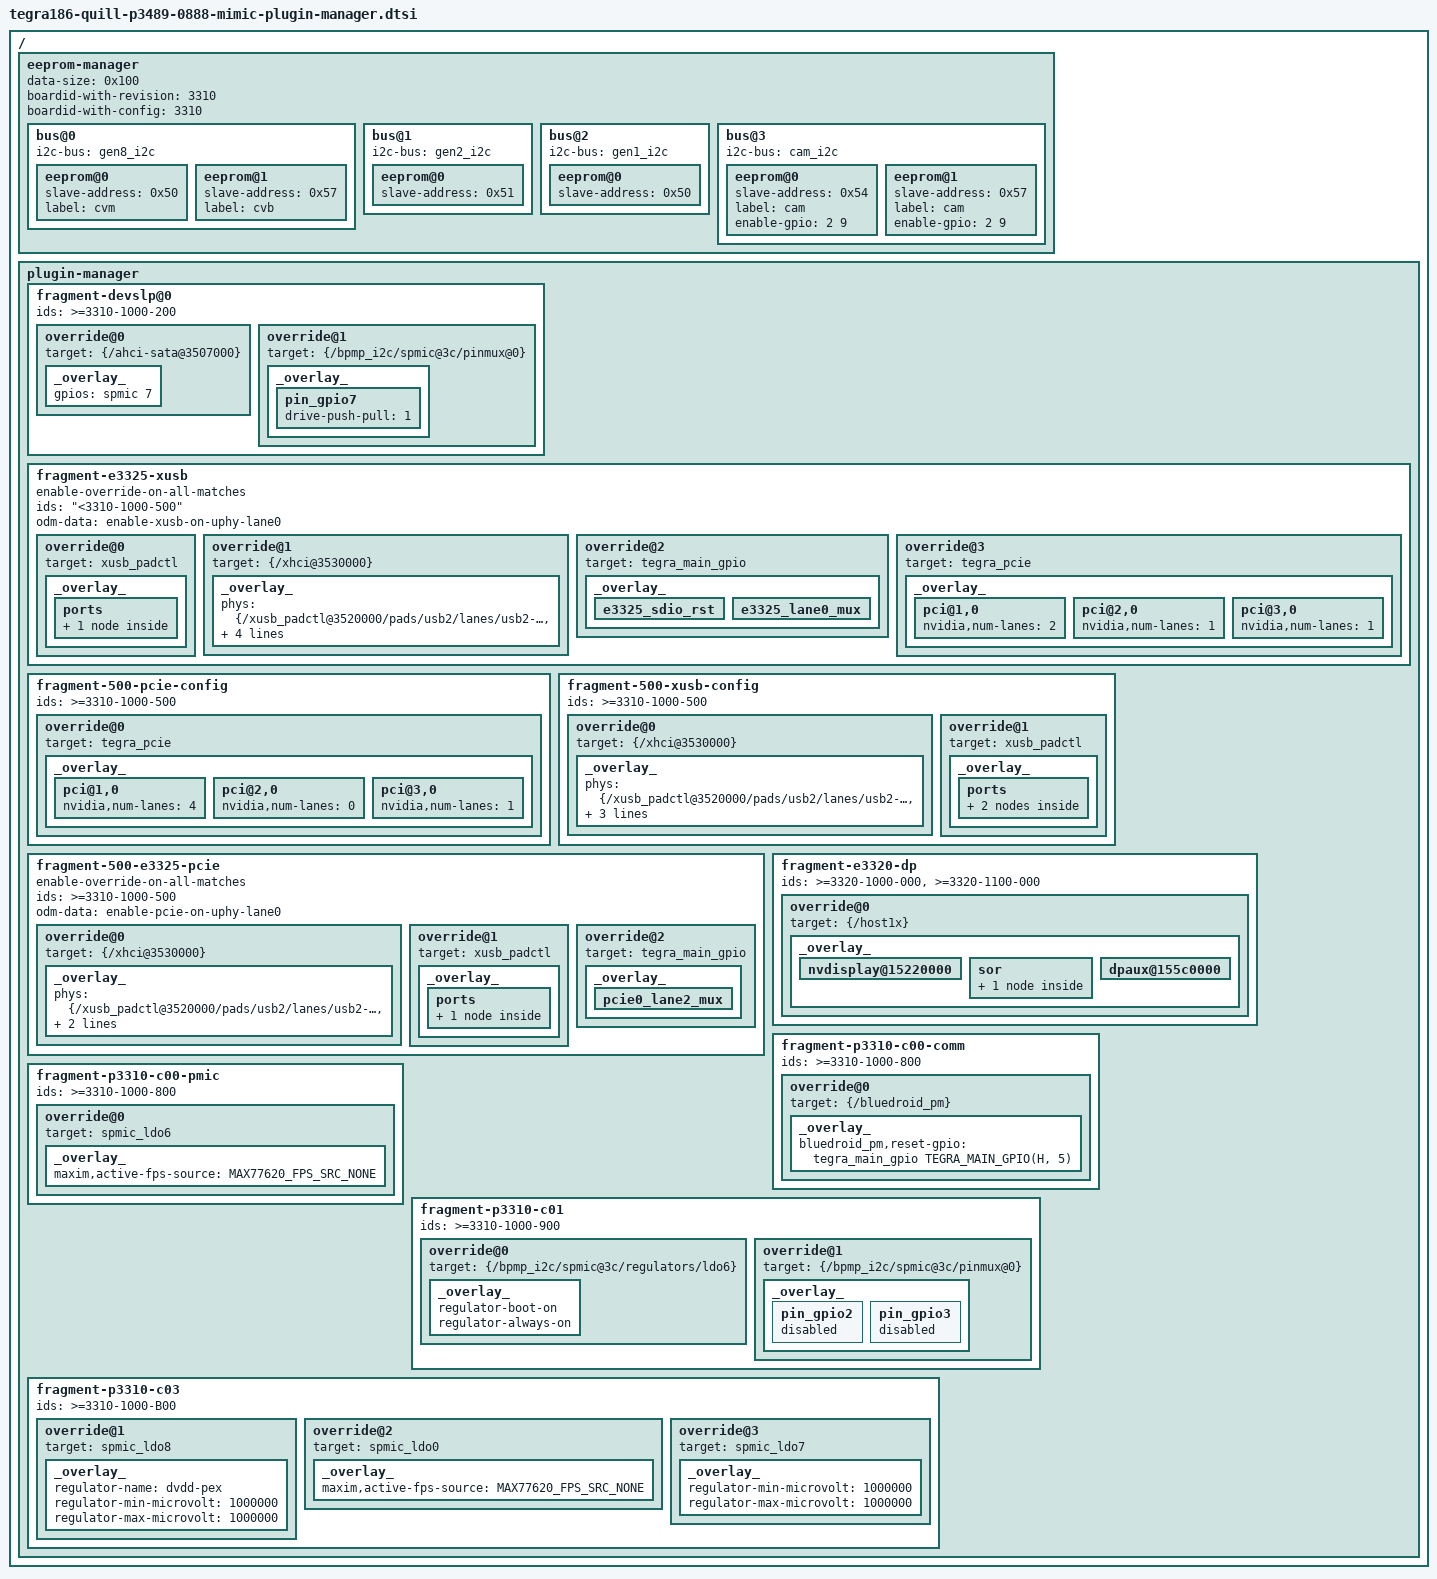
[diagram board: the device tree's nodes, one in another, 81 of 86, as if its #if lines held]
/*
 * tegra186-quill-p3489-0888-mimic-plugin-manager.dtsi: Lightning mimic plugin manager
 *
 * Copyright (c) 2015-2019, NVIDIA CORPORATION.  All rights reserved.
 *
 * This program is free software; you can redistribute it and/or modify
 * it under the terms of the GNU General Public License as published by
 * the Free Software Foundation; version 2 of the License.
 *
 * This program is distributed in the hope that it will be useful, but WITHOUT
 * ANY WARRANTY; without even the implied warranty of MERCHANTABILITY or
 * FITNESS FOR A PARTICULAR PURPOSE.  See the GNU General Public License for
 * more details.
 */

#include "tegra186-soc-prod-plugin-manager.dtsi"
#include "tegra186-odm-data-plugin-manager.dtsi"
#include "tegra186-quill-p3310-1000-300-plugin-manager.dtsi"

/ {
	eeprom-manager {
		data-size = <0x100>;
		boardid-with-revision = <3310>;
		boardid-with-config = <3310>;
		bus@0 {
			i2c-bus = <&gen8_i2c>;
			eeprom@0 {
				slave-address = <0x50>;
				label = "cvm";
			};
			eeprom@1 {
				slave-address = <0x57>;
				label = "cvb";
			};
		};
		bus@1 {
			i2c-bus = <&gen2_i2c>;
			eeprom@0 {
				slave-address = <0x51>;
			};
		};
		bus@2 {
			i2c-bus = <&gen1_i2c>;
			eeprom@0 {
				slave-address = <0x50>;
			};
		};
		bus@3 {
			i2c-bus = <&cam_i2c>;
			eeprom@0 {
				slave-address = <0x54>;
				label = "cam";
				enable-gpio = <2 9>;
			};
			eeprom@1 {
				slave-address = <0x57>;
				label = "cam";
				enable-gpio = <2 9>;
			};
		};
	};
	plugin-manager {
		fragment-devslp@0 {
			ids = ">=3310-1000-200";
			override@0 {
				target = <&{/ahci-sata@3507000}>;
				_overlay_ {
					gpios = <&spmic 7 0>;
				};
			};
			override@1 {
				target = <&{/bpmp_i2c/spmic@3c/pinmux@0}>;
				_overlay_ {
					pin_gpio7 {
						drive-push-pull = <1>;
					};
				};
			};
		};
		fragment-e3325-xusb {
			enable-override-on-all-matches;
			ids = "<3310-1000-500";
			odm-data = "enable-xusb-on-uphy-lane0";
			override@0 {
#if TEGRA_XUSB_PADCONTROL_VERSION >= DT_VERSION_2
				target = <&xusb_padctl>;
				_overlay_ {
					ports {
						usb3-0 {
							status = "okay";
						};
					};
				};
#else
				target = <&tegra_xusb_padctl_pinmux_default>;
				_overlay_ {
					e3325-usb3-std-A-HS {
						status = "okay";
					};
					e3325-usb3-std-A-SS {
						status = "okay";
					};
				};
#endif
			};
			override@1 {
				target = <&{/xhci@3530000}>;
#if TEGRA_XUSB_PADCONTROL_VERSION >= DT_VERSION_2
				_overlay_ {
					phys = <&{/xusb_padctl@3520000/pads/usb2/lanes/usb2-0}>,
						<&{/xusb_padctl@3520000/pads/usb2/lanes/usb2-1}>,
						<&{/xusb_padctl@3520000/pads/usb2/lanes/usb2-2}>,
						<&{/xusb_padctl@3520000/pads/usb3/lanes/usb3-0}>,
						<&{/xusb_padctl@3520000/pads/usb3/lanes/usb3-1}>;
					phy-names = "usb2-0", "usb2-1", "usb2-2", "usb3-0", "usb3-1";
				};
#else
				_overlay_ {
					phys = <&tegra_xusb_padctl TEGRA_PADCTL_PHY_UTMI_P(0)>,
							<&tegra_xusb_padctl TEGRA_PADCTL_PHY_UTMI_P(1)>,
							<&tegra_xusb_padctl TEGRA_PADCTL_PHY_USB3_P(1)>,
							<&tegra_xusb_padctl TEGRA_PADCTL_PHY_UTMI_P(2)>,
							<&tegra_xusb_padctl TEGRA_PADCTL_PHY_USB3_P(0)>;
					phy-names = "utmi-0", "utmi-1", "usb3-1", "utmi-2", "usb3-0";
				};
#endif
			};
			override@2 {
				target = <&tegra_main_gpio>;
				_overlay_ {
					e3325_sdio_rst {
						status = "okay";
					};
					e3325_lane0_mux {
						status = "okay";
					};
				};
			};
			override@3 {
				target = <&tegra_pcie>;
				_overlay_ {
					pci@1,0 {
						nvidia,num-lanes = <2>;
					};
					pci@2,0 {
						nvidia,num-lanes = <1>;
					};
					pci@3,0 {
						nvidia,num-lanes = <1>;
					};
				};
			};
		};
		fragment-500-pcie-config {
			ids = ">=3310-1000-500";
			override@0 {
				target = <&tegra_pcie>;
				_overlay_ {
					pci@1,0 {
						nvidia,num-lanes = <4>;
					};
					pci@2,0 {
						nvidia,num-lanes = <0>;
					};
					pci@3,0 {
						nvidia,num-lanes = <1>;
					};
				};
			};
		};
		fragment-500-xusb-config {
			ids = ">=3310-1000-500";
			override@0 {
				target = <&{/xhci@3530000}>;
#if TEGRA_XUSB_PADCONTROL_VERSION >= DT_VERSION_2
				_overlay_ {
					phys = <&{/xusb_padctl@3520000/pads/usb2/lanes/usb2-0}>,
						<&{/xusb_padctl@3520000/pads/usb2/lanes/usb2-1}>,
						<&{/xusb_padctl@3520000/pads/usb2/lanes/usb2-2}>,
						<&{/xusb_padctl@3520000/pads/usb3/lanes/usb3-0}>;
					phy-names = "usb2-0", "usb2-1", "usb2-2", "usb3-0";
				};
#else
				_overlay_ {
					phys = <&tegra_xusb_padctl TEGRA_PADCTL_PHY_UTMI_P(0)>,
						<&tegra_xusb_padctl TEGRA_PADCTL_PHY_UTMI_P(1)>,
						<&tegra_xusb_padctl TEGRA_PADCTL_PHY_UTMI_P(2)>,
						<&tegra_xusb_padctl TEGRA_PADCTL_PHY_USB3_P(0)>;
					phy-names = "utmi-0", "utmi-1", "utmi-2", "usb3-0";
				};
#endif
			};
			override@1 {
#if TEGRA_XUSB_PADCONTROL_VERSION >= DT_VERSION_2
				target = <&xusb_padctl>;
				_overlay_ {
					ports {
						usb3-1 {
							status = "disabled";
						};
						usb3-0 {
							nvidia,usb2-companion = <1>;
							status = "okay";
						};
					};
				};
#else
				target = <&tegra_xusb_padctl_pinmux_default>;
				_overlay_ {
					usb3-std-A-port2 {
						nvidia,lanes = "usb3-0";
					};
					e3325-usb3-std-A-HS {
						status = "okay";
					};
				};
#endif
			};
		};
		fragment-500-e3325-pcie {
			enable-override-on-all-matches;
			ids = ">=3310-1000-500";
			odm-data = "enable-pcie-on-uphy-lane0";
			override@0 {
				target = <&{/xhci@3530000}>;
#if TEGRA_XUSB_PADCONTROL_VERSION >= DT_VERSION_2
				_overlay_ {
					phys = <&{/xusb_padctl@3520000/pads/usb2/lanes/usb2-0}>,
						<&{/xusb_padctl@3520000/pads/usb2/lanes/usb2-1}>,
						<&{/xusb_padctl@3520000/pads/usb2/lanes/usb2-2}>;
					phy-names = "usb2-0", "usb2-1", "usb2-2";
				};
#else
				_overlay_ {
					phys = <&tegra_xusb_padctl TEGRA_PADCTL_PHY_UTMI_P(0)>,
						<&tegra_xusb_padctl TEGRA_PADCTL_PHY_UTMI_P(1)>,
						<&tegra_xusb_padctl TEGRA_PADCTL_PHY_UTMI_P(2)>;
					phy-names = "utmi-0", "utmi-1", "utmi-2";
				};
#endif
			};
			override@1 {
#if TEGRA_XUSB_PADCONTROL_VERSION >= DT_VERSION_2
				target = <&xusb_padctl>;
				_overlay_ {
					ports {
						usb3-0 {
							status = "disabled";
						};
					};
				};
#else
				target = <&tegra_xusb_padctl_pinmux_default>;
				_overlay_ {
					usb3-std-A-port2 {
						status = "disabled";
					};
				};
#endif
			};

			override@2 {
				target = <&tegra_main_gpio>;
				_overlay_ {
					pcie0_lane2_mux {
						status = "okay";
					};
				};
			};
		};

		fragment-e3320-dp {
			ids = ">=3320-1000-000", ">=3320-1100-000";
			override@0 {
				target = <&{/host1x}>;
				_overlay_ {
					nvdisplay@15220000 {
						status = "okay";
					};
					sor {
						status = "okay";
						dp-display {
							status = "okay";
						};
					};
					dpaux@155c0000 {
						status = "okay";
					};
				};
			};
		};

		fragment-p3310-c00-comm {
			ids = ">=3310-1000-800";
			override@0 {
				target = <&{/bluedroid_pm}>;
				_overlay_ {
					bluedroid_pm,reset-gpio = <&tegra_main_gpio TEGRA_MAIN_GPIO(H, 5) 0>;
				};
			};
		};

		fragment-p3310-c00-pmic {
			ids = ">=3310-1000-800";
			override@0 {
				target = <&spmic_ldo6>;
				_overlay_ {
					maxim,active-fps-source = <MAX77620_FPS_SRC_NONE>;
				};
			};
		};

		fragment-p3310-c01 {
			ids = ">=3310-1000-900";
			override@0 {
				target = <&{/bpmp_i2c/spmic@3c/regulators/ldo6}>;
				_overlay_ {
					regulator-boot-on;
					regulator-always-on;
				};
			};
			override@1 {
				target = <&{/bpmp_i2c/spmic@3c/pinmux@0}>;
				_overlay_ {
					pin_gpio2 {
						status = "disabled";
					};
					pin_gpio3 {
						status = "disabled";
					};
				};
			};
		};

		fragment-p3310-c03 {
			ids = ">=3310-1000-B00";

			override@1 {
				target = <&spmic_ldo8>;
				_overlay_ {
					regulator-name = "dvdd-pex";
					regulator-min-microvolt = <1000000>;
					regulator-max-microvolt = <1000000>;
				};
			};

			override@2 {
				target = <&spmic_ldo0>;
				_overlay_ {
					maxim,active-fps-source = <MAX77620_FPS_SRC_NONE>;
				};
			};

			override@3 {
				target = <&spmic_ldo7>;
				_overlay_ {
					regulator-min-microvolt = <1000000>;
					regulator-max-microvolt = <1000000>;
				};
			};
		};
	};
};
